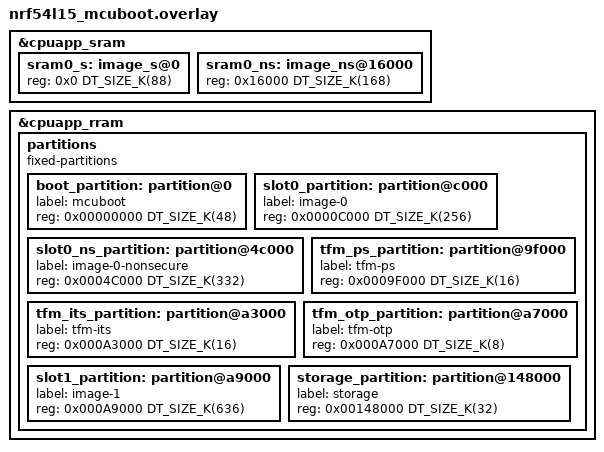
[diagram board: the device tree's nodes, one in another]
/*
 * Copyright (c) 2026 Nordic Semiconductor ASA
 *
 * SPDX-License-Identifier: LicenseRef-Nordic-5-Clause
 */

/*
 * TF-M partition layout with MCUboot for nRF54L15
 *
 * nRF54L15 has 1524 kB of RRAM and 256 kB of SRAM.
 * TrustZone flash region alignment: 4 kB (MPC-based)
 * TrustZone RAM region alignment:   4 kB
 * RRAM erase-block-size:            4 kB
 *
 * This layout includes MCUboot for DFU support with:
 * - MCUboot bootloader partition
 * - Primary slot (TF-M secure + NS application)
 * - Secondary slot (for DFU image)
 * - TF-M storage partitions (PS, ITS, OTP)
 * - Non-secure storage for application data
 *
 * Suitable for: products requiring firmware update capability
 */

&cpuapp_sram {
	sram0_s: image_s@0 {
		#address-cells = <1>;
		#size-cells = <1>;
		reg = <0x0 DT_SIZE_K(88)>;
		ranges = <0x0 0x0 DT_SIZE_K(88)>;
	};

	sram0_ns: image_ns@16000 {
		#address-cells = <1>;
		#size-cells = <1>;
		reg = <0x16000 DT_SIZE_K(168)>;
		ranges = <0x0 0x16000 DT_SIZE_K(168)>;
	};
};

&cpuapp_rram {
	partitions {
		compatible = "fixed-partitions";
		#address-cells = <1>;
		#size-cells = <1>;

		/*
		 * Flash layout (all addresses 4 kB aligned):
		 *
		 * 0x00000000  MCUboot bootloader       (48 kB)
		 * 0x0000C000  Primary slot:
		 *   0x0000C000  TF-M secure image      (256 kB)
		 *   0x0004C000  Non-secure application  (332 kB)
		 * 0x0009F000  TF-M PS                   (16 kB)
		 * 0x000A3000  TF-M ITS                  (16 kB)
		 * 0x000A7000  TF-M OTP / NV counters     (8 kB)
		 * 0x000A9000  Secondary slot            (636 kB)
		 * 0x00148000  Non-secure storage         (32 kB)
		 *
		 * Note: secondary slot should be >= primary slot (TF-M + NS)
		 *       Primary = 256 + 332 = 588 kB
		 *       Secondary = 636 kB (allows some headroom)
		 */

		boot_partition: partition@0 {
			label = "mcuboot";
			reg = <0x00000000 DT_SIZE_K(48)>;
		};

		slot0_partition: partition@c000 {
			label = "image-0";
			reg = <0x0000C000 DT_SIZE_K(256)>;
		};

		slot0_ns_partition: partition@4c000 {
			label = "image-0-nonsecure";
			reg = <0x0004C000 DT_SIZE_K(332)>;
		};

		tfm_ps_partition: partition@9f000 {
			label = "tfm-ps";
			reg = <0x0009F000 DT_SIZE_K(16)>;
		};

		tfm_its_partition: partition@a3000 {
			label = "tfm-its";
			reg = <0x000A3000 DT_SIZE_K(16)>;
		};

		tfm_otp_partition: partition@a7000 {
			label = "tfm-otp";
			reg = <0x000A7000 DT_SIZE_K(8)>;
		};

		slot1_partition: partition@a9000 {
			label = "image-1";
			reg = <0x000A9000 DT_SIZE_K(636)>;
		};

		storage_partition: partition@148000 {
			label = "storage";
			reg = <0x00148000 DT_SIZE_K(32)>;
		};
	};
};
